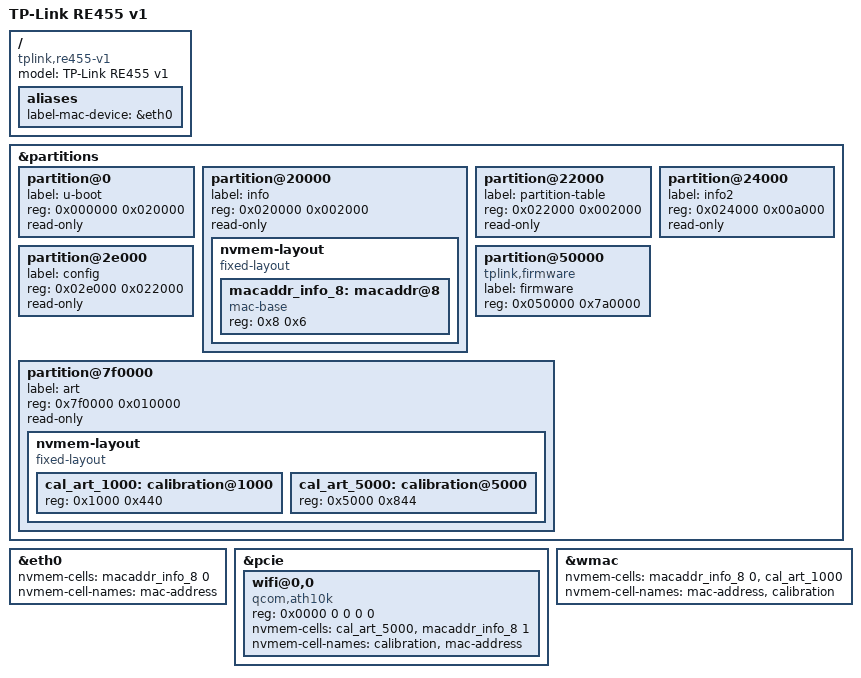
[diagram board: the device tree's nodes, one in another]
// SPDX-License-Identifier: GPL-2.0-or-later OR MIT

#include "qca9563_tplink_re450.dtsi"

/ {
	compatible = "tplink,re455-v1", "qca,qca9563";
	model = "TP-Link RE455 v1";

	aliases {
		label-mac-device = &eth0;
	};
};

&partitions {
	partition@0 {
		label = "u-boot";
		reg = <0x000000 0x020000>;
		read-only;
	};

	partition@20000 {
		label = "info";
		reg = <0x020000 0x002000>;
		read-only;

		nvmem-layout {
			compatible = "fixed-layout";
			#address-cells = <1>;
			#size-cells = <1>;

			macaddr_info_8: macaddr@8 {
				compatible = "mac-base";
				reg = <0x8 0x6>;
				#nvmem-cell-cells = <1>;
			};
		};
	};

	partition@22000 {
		label = "partition-table";
		reg = <0x022000 0x002000>;
		read-only;
	};

	partition@24000 {
		label = "info2";
		reg = <0x024000 0x00a000>;
		read-only;
	};

	partition@2e000 {
		label = "config";
		reg = <0x02e000 0x022000>;
		read-only;
	};

	partition@50000 {
		compatible = "tplink,firmware";
		label = "firmware";
		reg = <0x050000 0x7a0000>;
	};

	partition@7f0000 {
		label = "art";
		reg = <0x7f0000 0x010000>;
		read-only;

		nvmem-layout {
			compatible = "fixed-layout";
			#address-cells = <1>;
			#size-cells = <1>;

			cal_art_1000: calibration@1000 {
				reg = <0x1000 0x440>;
			};

			cal_art_5000: calibration@5000 {
				reg = <0x5000 0x844>;
			};
		};
	};
};

&eth0 {
	nvmem-cells = <&macaddr_info_8 0>;
	nvmem-cell-names = "mac-address";
};

&pcie {
	wifi@0,0 {
		compatible = "qcom,ath10k";
		reg = <0x0000 0 0 0 0>;
		nvmem-cells = <&cal_art_5000>, <&macaddr_info_8 1>;
		nvmem-cell-names = "calibration", "mac-address";
	};
};

&wmac {
	nvmem-cells = <&macaddr_info_8 0>, <&cal_art_1000>;
	nvmem-cell-names = "mac-address", "calibration";
};
